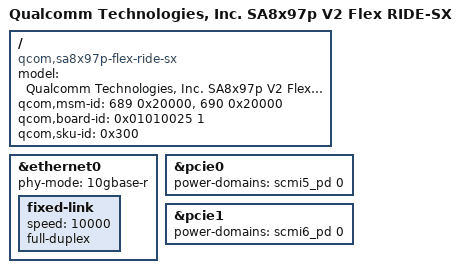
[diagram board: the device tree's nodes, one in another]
// SPDX-License-Identifier: BSD-3-Clause
/*
 * Copyright (c) Qualcomm Technologies, Inc. and/or its subsidiaries.
 */

/dts-v1/;

#include "sa8x97p.dtsi"
#include "sa8x97p-v2.dtsi"
#include "sa8797p.dtsi"
#include "sa8x97p-safe.dtsi"

/ {
	model = "Qualcomm Technologies, Inc. SA8x97p V2 Flex RIDE-SX";
	compatible = "qcom,sa8x97p-flex-ride-sx", "qcom,sa8x97p-qam", "qcom,sa8797p";
	qcom,msm-id = <689 0x20000>, <690 0x20000>;
	qcom,board-id = <0x01010025 1>;
	qcom,sku-id = <0x300>;
};

&ethernet0 {
	phy-mode = "10gbase-r";

	fixed-link {
		status = "okay";
		speed = <10000>;
		full-duplex;
	};
};

&pcie0 {
	power-domains = <&scmi5_pd 0>;
	power-domain-names = "power";
	status = "okay";
};

&pcie1 {
	power-domains = <&scmi6_pd 0>;
	power-domain-names = "power";
	status = "okay";
};
